AUTOSAR XML (schema 314)
package /ComponentType
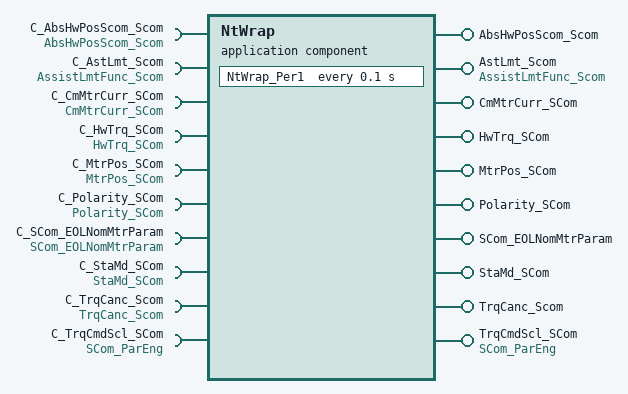
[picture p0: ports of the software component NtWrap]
  application software component type NtWrap
    10 x provide port:
      AbsHwPosScom_Scom: provided-com-specs=[{operation=HwPosSrvRead, queue-length=1}, {operation=HwPosSrvSetToZero, queue-length=1}], provided-interface=AbsHwPosScom_Scom
      AstLmt_Scom: provided-interface=AssistLmtFunc_Scom
        provided-com-specs:
          operation=GetSteeringAssistDefeat, queue-length=1
          operation=ManualTrqCmd, queue-length=1
          operation=SetSteeringAssistDefeat, queue-length=1
      CmMtrCurr_SCom: provided-interface=CmMtrCurr_SCom
        provided-com-specs:
          operation=CalGain, queue-length=1
          operation=CalOffset, queue-length=1
          operation=MtrCurrOffReadStatus, queue-length=1
          operation=ReadMtrCurrCals, queue-length=1
          operation=SetMtrCurrCals, queue-length=1
      HwTrq_SCom: provided-interface=HwTrq_SCom
        provided-com-specs:
          operation=ClrHwTrqScale, queue-length=1
          operation=ClrHwTrqTrim, queue-length=1
          operation=ManualSetHwTrqTrim, queue-length=1
          operation=ReadEOLTrqStep, queue-length=1
          operation=ReadHwTrqScale, queue-length=1
          operation=ReadHwTrqTrim, queue-length=1
          operation=SetEOLTrqStep, queue-length=1
          operation=SetHwTrqScale, queue-length=1
          operation=SetHwTrqTrim, queue-length=1
      MtrPos_SCom: provided-com-specs=[{operation=ReadEOLMtrCals, queue-length=1}, {operation=SetEOLMtrCals, queue-length=1}], provided-interface=MtrPos_SCom
      Polarity_SCom: provided-com-specs=[{operation=ReadPolarity, queue-length=1}, {operation=SetPolarity, queue-length=1}], provided-interface=Polarity_SCom
      SCom_EOLNomMtrParam: provided-com-specs=[{operation=Get, queue-length=1}, {operation=Set, queue-length=1}], provided-interface=SCom_EOLNomMtrParam
      StaMd_SCom: server-com-spec{operation=EcuReset, queue-length=1}, provided-interface=StaMd_SCom
      TrqCanc_Scom: provided-interface=TrqCanc_Scom
        provided-com-specs:
          operation=ReadCogTrqCal, queue-length=1
          operation=ReadCogTrqCalComp, queue-length=1
          operation=SetCogTrqCal, queue-length=1
          operation=SetCogTrqCalComp, queue-length=1
      TrqCmdScl_SCom: provided-com-specs=[{operation=Get, queue-length=1}, {operation=Set, queue-length=1}], provided-interface=SCom_ParEng
    10 x require port:
      C_AbsHwPosScom_Scom: required-com-specs=[HwPosSrvRead, HwPosSrvSetToZero], required-interface=AbsHwPosScom_Scom
      C_AstLmt_Scom: required-com-specs=[GetSteeringAssistDefeat, ManualTrqCmd, SetSteeringAssistDefeat], required-interface=AssistLmtFunc_Scom
      C_CmMtrCurr_SCom: required-com-specs=[CalGain, CalOffset, MtrCurrOffReadStatus, ReadMtrCurrCals, SetMtrCurrCals], required-interface=CmMtrCurr_SCom
      C_HwTrq_SCom: required-interface=HwTrq_SCom
        required-com-specs:
          ClrHwTrqScale
          ClrHwTrqTrim
          ManualSetHwTrqTrim
          ReadEOLTrqStep
          ReadHwTrqScale
          ReadHwTrqTrim
          SetEOLTrqStep
          SetHwTrqScale
          SetHwTrqTrim
      C_MtrPos_SCom: required-com-specs=[ReadEOLMtrCals, SetEOLMtrCals], required-interface=MtrPos_SCom
      C_Polarity_SCom: required-com-specs=[ReadPolarity, SetPolarity], required-interface=Polarity_SCom
      C_SCom_EOLNomMtrParam: required-com-specs=[Get, Set], required-interface=SCom_EOLNomMtrParam
      C_StaMd_SCom: client-com-spec=EcuReset, required-interface=StaMd_SCom
      C_TrqCanc_Scom: required-com-specs=[ReadCogTrqCal, ReadCogTrqCalComp, SetCogTrqCal, SetCogTrqCalComp], required-interface=TrqCanc_Scom
      C_TrqCmdScl_SCom: required-com-specs=[Get, Set], required-interface=SCom_ParEng
  internal behavior NtWrap_InternalBehavior: component=NtWrap
    12 x operation invoked event:
      OIT_AbsHwPosScom_Scom_HwPosSrvSetToZero_AbsHwPosScom_Scom_HwPosSrvSetToZero: start-on-event=AbsHwPosScom_Scom_HwPosSrvSetToZero, operation=AbsHwPosScom_Scom.HwPosSrvSetToZero
      OIT_AstLmt_Scom_ManualTrqCmd_AstLmt_Scom_ManualTrqCmd: start-on-event=AstLmt_Scom_ManualTrqCmd, operation=AstLmt_Scom.ManualTrqCmd
      OIT_CmMtrCurr_SCom_CalGain_CmMtrCurr_SCom_CalGain: start-on-event=CmMtrCurr_SCom_CalGain, operation=CmMtrCurr_SCom.CalGain
      OIT_CmMtrCurr_SCom_CalOffset_CmMtrCurr_SCom_CalOffset: start-on-event=CmMtrCurr_SCom_CalOffset, operation=CmMtrCurr_SCom.CalOffset
      OIT_CmMtrCurr_SCom_SetMtrCurrCals_CmMtrCurr_SCom_SetMtrCurrCals: start-on-event=CmMtrCurr_SCom_SetMtrCurrCals, operation=CmMtrCurr_SCom.SetMtrCurrCals
      OIT_HwTrq_SCom_ClrHwTrqScale_HwTrq_SCom_ClrHwTrqScale: start-on-event=HwTrq_SCom_ClrHwTrqScale, operation=HwTrq_SCom.ClrHwTrqScale
      OIT_HwTrq_SCom_ClrHwTrqTrim_HwTrq_SCom_ClrHwTrqTrim: start-on-event=HwTrq_SCom_ClrHwTrqTrim, operation=HwTrq_SCom.ClrHwTrqTrim
      OIT_HwTrq_SCom_ManualSetHwTrqTrim_HwTrq_SCom_ManualSetHwTrqTrim: start-on-event=HwTrq_SCom_ManualSetHwTrqTrim, operation=HwTrq_SCom.ManualSetHwTrqTrim
      OIT_HwTrq_SCom_SetEOLTrqStep_HwTrq_SCom_SetEOLTrqStep: start-on-event=HwTrq_SCom_SetEOLTrqStep, operation=HwTrq_SCom.SetEOLTrqStep
      OIT_HwTrq_SCom_SetHwTrqScale_HwTrq_SCom_SetHwTrqScale: start-on-event=HwTrq_SCom_SetHwTrqScale, operation=HwTrq_SCom.SetHwTrqScale
      OIT_HwTrq_SCom_SetHwTrqTrim_HwTrq_SCom_SetHwTrqTrim: start-on-event=HwTrq_SCom_SetHwTrqTrim, operation=HwTrq_SCom.SetHwTrqTrim
      OIT_MtrPos_SCom_SetEOLMtrCals_MtrPos_SCom_SetEOLMtrCals: start-on-event=MtrPos_SCom_SetEOLMtrCals, operation=MtrPos_SCom.SetEOLMtrCals
    timing event TMT_NtWrap_Per1: start-on-event=NtWrap_Per1, period=0.1
    5 x operation invoked event:
      OIT_Polarity_SCom_SetPolarity_Polarity_SCom_SetPolarity: start-on-event=Polarity_SCom_SetPolarity, operation=Polarity_SCom.SetPolarity
      OIT_SCom_EOLNomMtrParam_Set_SCom_EOLNomMtrParam_Set: start-on-event=SCom_EOLNomMtrParam_Set, operation=SCom_EOLNomMtrParam.Set
      OIT_StaMd_SCom_EcuReset_StaMd_SCom_EcuReset: start-on-event=StaMd_SCom_EcuReset, operation=StaMd_SCom.EcuReset
      OIT_TrqCanc_Scom_SetCogTrqCal_TrqCanc_Scom_SetCogTrqCal: start-on-event=TrqCanc_Scom_SetCogTrqCal, operation=TrqCanc_Scom.SetCogTrqCal
      OIT_TrqCmdScl_SCom_Set_TrqCmdScl_SCom_Set: start-on-event=TrqCmdScl_SCom_Set, operation=TrqCmdScl_SCom.Set
    port-api-options:
      enable-take-address=false, indirect-api=false, port=AbsHwPosScom_Scom
      enable-take-address=false, indirect-api=false, port=AstLmt_Scom
      enable-take-address=false, indirect-api=false, port=C_AbsHwPosScom_Scom
      enable-take-address=false, indirect-api=false, port=C_AstLmt_Scom
      enable-take-address=false, indirect-api=false, port=C_CmMtrCurr_SCom
      enable-take-address=false, indirect-api=false, port=C_HwTrq_SCom
      enable-take-address=false, indirect-api=false, port=C_MtrPos_SCom
      enable-take-address=false, indirect-api=false, port=C_Polarity_SCom
      enable-take-address=false, indirect-api=false, port=C_SCom_EOLNomMtrParam
      enable-take-address=false, indirect-api=false, port=C_StaMd_SCom
      enable-take-address=false, indirect-api=false, port=C_TrqCanc_Scom
      enable-take-address=false, indirect-api=false, port=C_TrqCmdScl_SCom
      enable-take-address=false, indirect-api=false, port=CmMtrCurr_SCom
      enable-take-address=false, indirect-api=false, port=HwTrq_SCom
      enable-take-address=false, indirect-api=false, port=MtrPos_SCom
      enable-take-address=false, indirect-api=false, port=Polarity_SCom
      enable-take-address=false, indirect-api=false, port=SCom_EOLNomMtrParam
      enable-take-address=false, indirect-api=false, port=StaMd_SCom
      enable-take-address=false, indirect-api=false, port=TrqCanc_Scom
      enable-take-address=false, indirect-api=false, port=TrqCmdScl_SCom
    18 x runnable:
      AbsHwPosScom_Scom_HwPosSrvSetToZero: symbol=NtWrapC_AbsHwPosScom_Scom_HwPosSrvSetToZero
        sync call SC_C_AbsHwPosScom_Scom_HwPosSrvSetToZero: operation=C_AbsHwPosScom_Scom.HwPosSrvSetToZero, timeout=0
      AstLmt_Scom_ManualTrqCmd: symbol=NtWrapC_AstLmt_Scom_ManualTrqCmd
        sync call SC_C_AstLmt_Scom_ManualTrqCmd: operation=C_AstLmt_Scom.ManualTrqCmd, timeout=0
      CmMtrCurr_SCom_CalGain: symbol=NtWrapC_CmMtrCurr_SCom_CalGain
        sync call SC_C_CmMtrCurr_SCom_CalGain: operation=C_CmMtrCurr_SCom.CalGain, timeout=0
      CmMtrCurr_SCom_CalOffset: symbol=NtWrapC_CmMtrCurr_SCom_CalOffset
        sync call SC_C_CmMtrCurr_SCom_CalOffset: operation=C_CmMtrCurr_SCom.CalOffset, timeout=0
      CmMtrCurr_SCom_SetMtrCurrCals: symbol=NtWrapC_CmMtrCurr_SCom_SetMtrCurrCals
        sync call SC_C_CmMtrCurr_SCom_SetMtrCurrCals: operation=C_CmMtrCurr_SCom.SetMtrCurrCals, timeout=0
      HwTrq_SCom_ClrHwTrqScale: symbol=NtWrapC_HwTrq_SCom_ClrHwTrqScale
        sync call SC_C_HwTrq_SCom_ClrHwTrqScale: operation=C_HwTrq_SCom.ClrHwTrqScale, timeout=0
      HwTrq_SCom_ClrHwTrqTrim: symbol=NtWrapC_HwTrq_SCom_ClrHwTrqTrim
        sync call SC_C_HwTrq_SCom_ClrHwTrqTrim: operation=C_HwTrq_SCom.ClrHwTrqTrim, timeout=0
      HwTrq_SCom_ManualSetHwTrqTrim: symbol=NtWrapC_HwTrq_SCom_ManualSetHwTrqTrim
        sync call SC_C_HwTrq_SCom_ManualSetHwTrqTrim: operation=C_HwTrq_SCom.ManualSetHwTrqTrim, timeout=0
      HwTrq_SCom_SetEOLTrqStep: symbol=NtWrapC_HwTrq_SCom_SetEOLTrqStep
        sync call SC_C_HwTrq_SCom_SetEOLTrqStep: operation=C_HwTrq_SCom.SetEOLTrqStep, timeout=0
      HwTrq_SCom_SetHwTrqScale: symbol=NtWrapC_HwTrq_SCom_SetHwTrqScale
        sync call SC_C_HwTrq_SCom_SetHwTrqScale: operation=C_HwTrq_SCom.SetHwTrqScale, timeout=0
      HwTrq_SCom_SetHwTrqTrim: symbol=NtWrapC_HwTrq_SCom_SetHwTrqTrim
        sync call SC_C_HwTrq_SCom_SetHwTrqTrim: operation=C_HwTrq_SCom.SetHwTrqTrim, timeout=0
      MtrPos_SCom_SetEOLMtrCals: symbol=NtWrapC_MtrPos_SCom_SetEOLMtrCals
        sync call SC_C_MtrPos_SCom_SetEOLMtrCals: operation=C_MtrPos_SCom.SetEOLMtrCals, timeout=0
      NtWrap_Per1  # Dummy function to map this component onto an application for generation.
      Polarity_SCom_SetPolarity: symbol=NtWrapC_Polarity_SCom_SetPolarity
        sync call SC_C_Polarity_SCom_SetPolarity: operation=C_Polarity_SCom.SetPolarity, timeout=0
      SCom_EOLNomMtrParam_Set: symbol=NtWrapC_SCom_EOLNomMtrParam_Set
        sync call SC_C_SCom_EOLNomMtrParam_Set: operation=C_SCom_EOLNomMtrParam.Set, timeout=0
      StaMd_SCom_EcuReset: symbol=NtWrapC_StaMd_SCom_EcuReset
        sync call SC_C_StaMd_SCom_EcuReset: operation=C_StaMd_SCom.EcuReset, timeout=0
      TrqCanc_Scom_SetCogTrqCal: symbol=NtWrapC_TrqCanc_Scom_SetCogTrqCal
        sync call SC_C_TrqCanc_Scom_SetCogTrqCal: operation=C_TrqCanc_Scom.SetCogTrqCal, timeout=0
      TrqCmdScl_SCom_Set: symbol=NtWrapC_TrqCmdScl_SCom_Set
        sync call SC_C_TrqCmdScl_SCom_Set: operation=C_TrqCmdScl_SCom.Set, timeout=0
  swc implementation NtWrap_Implementation: behavior=NtWrap_InternalBehavior
    code-descriptors:
      code Code: type=SRC
